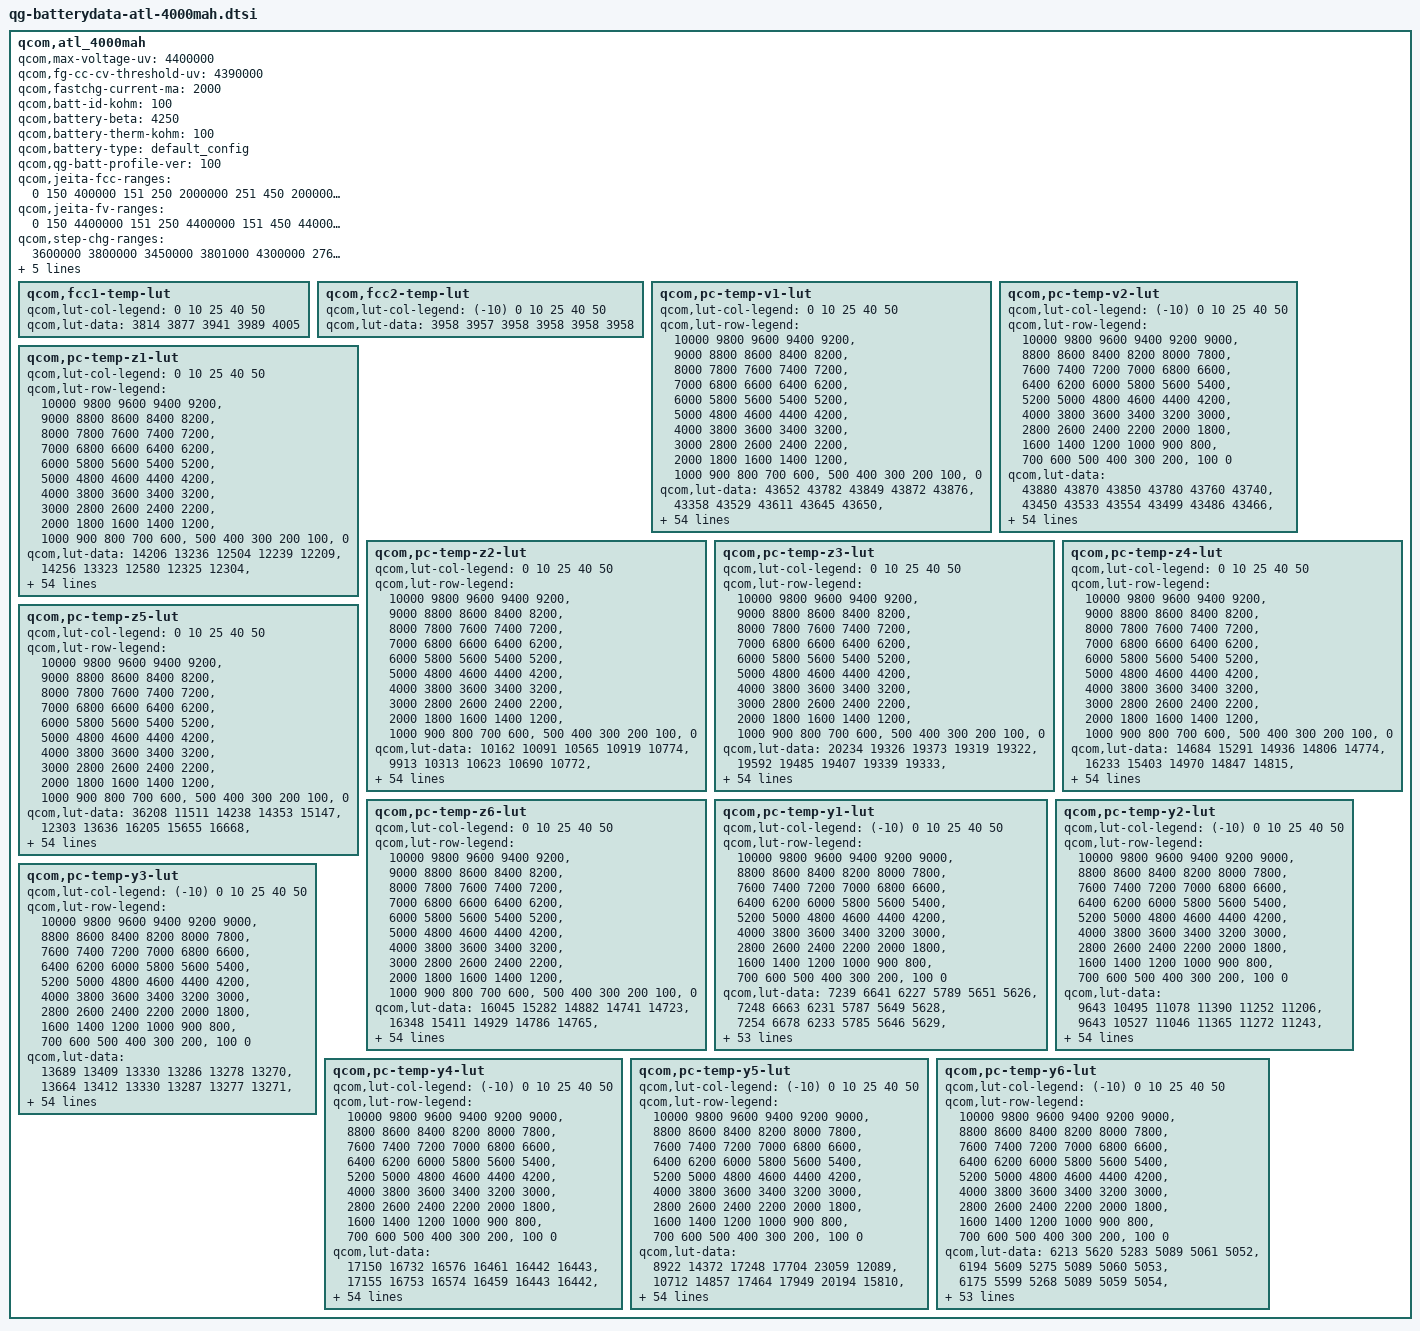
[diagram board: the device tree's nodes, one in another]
// SPDX-License-Identifier: GPL-2.0
/*
 * Copyright (c) 2018-2019, The Linux Foundation. All rights reserved.
 */

qcom,atl_4000mah {
    /* 4124117_LC_M516_ATL_4000mAH_PMI632_averaged_MasterSlave_Jul25th2019 */
	qcom,max-voltage-uv = <4400000>;
	qcom,fg-cc-cv-threshold-uv = <4390000>;
	qcom,fastchg-current-ma = <2000>;
	qcom,batt-id-kohm = <100>;
    	qcom,battery-beta = <4250>;
	qcom,battery-therm-kohm = <100>;
	qcom,battery-type = "default_config";
	qcom,qg-batt-profile-ver = <100>;

	qcom,jeita-fcc-ranges = <0   150   400000
                                151  250  2000000
                                251  450  2000000
                                451  600  2000000>;
        qcom,jeita-fv-ranges = <0    150   4400000
                                151  250  4400000
                                151  450  4400000
                                451  600  4100000>;
	qcom,step-chg-ranges = <3600000  3800000  3450000
				3801000  4300000  2760000
				4301000  4350000  2070000>;

	/* COOL = 15 DegC, WARM = 45 DegC */
	qcom,jeita-soft-thresholds = <0x4621 0x20B8>;
	/* COLD = 0 DegC, HOT = 52 DegC */
	qcom,jeita-hard-thresholds = <0x58CD 0x1A75>;

	qcom,jeita-soft-hys-thresholds = <0x44C4 0x21B5>;
	qcom,jeita-soft-fcc-ua = <500000 2000000>;
	qcom,jeita-soft-fv-uv = <4400000 4100000>;

	qcom,fcc1-temp-lut {
		qcom,lut-col-legend = <0 10 25 40 50>;
		qcom,lut-data = <3814 3877 3941 3989 4005>;
	};

	qcom,fcc2-temp-lut {
		qcom,lut-col-legend = <(-10) 0 10 25 40 50>;
		qcom,lut-data = <3958 3957 3958 3958 3958 3958>;
	};

	qcom,pc-temp-v1-lut {
		qcom,lut-col-legend = <0 10 25 40 50>;
		qcom,lut-row-legend = <10000 9800 9600 9400 9200>,
			<9000 8800 8600 8400 8200>,
			<8000 7800 7600 7400 7200>,
			<7000 6800 6600 6400 6200>,
			<6000 5800 5600 5400 5200>,
			<5000 4800 4600 4400 4200>,
			<4000 3800 3600 3400 3200>,
			<3000 2800 2600 2400 2200>,
			<2000 1800 1600 1400 1200>,
			<1000 900 800 700 600>,
			<500 400 300 200 100>,
			<0>;
		qcom,lut-data = <43652 43782 43849 43872 43876>,
			<43358 43529 43611 43645 43650>,
			<43078 43260 43365 43407 43414>,
			<42809 42984 43105 43154 43168>,
			<42552 42718 42837 42886 42909>,
			<42305 42462 42577 42623 42650>,
			<42066 42214 42322 42371 42398>,
			<41833 41975 42074 42125 42149>,
			<41610 41744 41831 41882 41905>,
			<41399 41520 41595 41645 41666>,
			<41195 41307 41366 41410 41431>,
			<40971 41095 41149 41176 41197>,
			<40710 40865 40929 40947 40967>,
			<40447 40617 40691 40725 40745>,
			<40208 40379 40446 40509 40529>,
			<39980 40153 40229 40302 40322>,
			<39787 39941 40044 40106 40124>,
			<39639 39763 39869 39916 39932>,
			<39511 39616 39698 39734 39744>,
			<39375 39472 39532 39560 39562>,
			<39232 39316 39335 39365 39367>,
			<39091 39153 39064 39105 39127>,
			<38956 38971 38806 38845 38882>,
			<38825 38742 38641 38680 38708>,
			<38705 38532 38513 38562 38580>,
			<38594 38398 38406 38455 38464>,
			<38494 38295 38314 38347 38351>,
			<38404 38222 38236 38249 38247>,
			<38321 38173 38166 38164 38157>,
			<38252 38135 38103 38088 38077>,
			<38198 38100 38051 38026 38010>,
			<38152 38069 38006 37976 37953>,
			<38118 38043 37970 37932 37904>,
			<38094 38023 37943 37895 37861>,
			<38073 38005 37923 37864 37826>,
			<38049 37983 37901 37832 37788>,
			<38027 37959 37876 37801 37748>,
			<37996 37926 37844 37766 37705>,
			<37948 37876 37795 37714 37647>,
			<37877 37801 37717 37637 37571>,
			<37777 37705 37618 37542 37478>,
			<37610 37577 37500 37438 37374>,
			<37320 37358 37315 37284 37223>,
			<36757 36837 36855 36932 36917>,
			<36237 36314 36327 36446 36464>,
			<35877 35901 35900 35984 36001>,
			<35747 35753 35751 35819 35838>,
			<35632 35620 35626 35683 35695>,
			<35508 35509 35502 35555 35566>,
			<35345 35372 35339 35400 35396>,
			<34997 35066 34966 35036 35006>,
			<34446 34538 34428 34509 34484>,
			<33778 33910 33757 33861 33832>,
			<32892 33082 32875 33021 32992>,
			<31612 31893 31570 31811 31771>,
			<30000 30000 30000 30000 30000>;
	};

	qcom,pc-temp-v2-lut {
		qcom,lut-col-legend = <(-10) 0 10 25 40 50>;
		qcom,lut-row-legend = <10000 9800 9600 9400 9200 9000>,
			<8800 8600 8400 8200 8000 7800>,
			<7600 7400 7200 7000 6800 6600>,
			<6400 6200 6000 5800 5600 5400>,
			<5200 5000 4800 4600 4400 4200>,
			<4000 3800 3600 3400 3200 3000>,
			<2800 2600 2400 2200 2000 1800>,
			<1600 1400 1200 1000 900 800>,
			<700 600 500 400 300 200>,
			<100 0>;
		qcom,lut-data = <43880 43870 43850 43780 43760 43740>,
			<43450 43533 43554 43499 43486 43466>,
			<43068 43216 43266 43222 43215 43197>,
			<42744 42917 42984 42948 42945 42929>,
			<42467 42637 42707 42675 42676 42665>,
			<42213 42370 42439 42410 42413 42406>,
			<41968 42114 42183 42153 42161 42153>,
			<41735 41867 41936 41905 41916 41905>,
			<41504 41621 41694 41659 41674 41663>,
			<41275 41371 41455 41417 41434 41426>,
			<41047 41141 41226 41183 41199 41194>,
			<40826 40953 41020 40967 40969 40964>,
			<40603 40779 40822 40757 40744 40738>,
			<40337 40552 40590 40529 40524 40519>,
			<39990 40222 40298 40265 40306 40305>,
			<39662 39901 40020 40023 40098 40099>,
			<39432 39671 39814 39848 39907 39906>,
			<39244 39474 39637 39701 39726 39723>,
			<39059 39278 39441 39525 39538 39533>,
			<38871 39076 39217 39302 39342 39341>,
			<38693 38885 38997 39071 39139 39142>,
			<38531 38711 38804 38854 38917 38921>,
			<38382 38549 38629 38645 38685 38689>,
			<38259 38400 38475 38476 38502 38505>,
			<38163 38252 38341 38344 38364 38366>,
			<38077 38129 38222 38230 38247 38249>,
			<37984 38047 38114 38129 38142 38143>,
			<37889 37985 38016 38037 38050 38049>,
			<37795 37934 37943 37959 37969 37965>,
			<37703 37889 37888 37886 37897 37889>,
			<37609 37852 37846 37828 37836 37824>,
			<37504 37824 37816 37790 37787 37773>,
			<37388 37803 37793 37762 37748 37732>,
			<37260 37779 37769 37737 37707 37686>,
			<37114 37757 37743 37716 37665 37632>,
			<36955 37729 37714 37692 37620 37572>,
			<36789 37682 37679 37652 37563 37501>,
			<36615 37603 37637 37590 37493 37420>,
			<36429 37490 37581 37518 37420 37341>,
			<36199 37286 37507 37447 37356 37278>,
			<35969 36996 37395 37353 37280 37208>,
			<35822 36641 37185 37187 37156 37096>,
			<35725 36188 36778 36874 36947 36908>,
			<35625 35805 36289 36412 36566 36558>,
			<35517 35496 35771 35851 36011 36032>,
			<35380 35286 35451 35531 35649 35666>,
			<35277 35191 35316 35410 35514 35525>,
			<35156 35090 35213 35300 35391 35396>,
			<34992 34978 35077 35178 35263 35269>,
			<34754 34813 34943 35009 35092 35076>,
			<34417 34497 34627 34636 34736 34677>,
			<33949 33992 34106 34077 34189 34131>,
			<33306 33305 33444 33375 33520 33444>,
			<32426 32375 32573 32453 32659 32555>,
			<31107 30949 31315 31083 31426 31328>,
			<26640 26496 29274 26924 29401 29238>;
	};

	qcom,pc-temp-z1-lut {
		qcom,lut-col-legend = <0 10 25 40 50>;
		qcom,lut-row-legend = <10000 9800 9600 9400 9200>,
			<9000 8800 8600 8400 8200>,
			<8000 7800 7600 7400 7200>,
			<7000 6800 6600 6400 6200>,
			<6000 5800 5600 5400 5200>,
			<5000 4800 4600 4400 4200>,
			<4000 3800 3600 3400 3200>,
			<3000 2800 2600 2400 2200>,
			<2000 1800 1600 1400 1200>,
			<1000 900 800 700 600>,
			<500 400 300 200 100>,
			<0>;
		qcom,lut-data = <14206 13236 12504 12239 12209>,
			<14256 13323 12580 12325 12304>,
			<14257 13357 12622 12382 12370>,
			<14259 13378 12630 12400 12393>,
			<14294 13383 12634 12408 12403>,
			<14337 13382 12634 12414 12411>,
			<14344 13381 12627 12418 12419>,
			<14340 13371 12621 12422 12428>,
			<14336 13346 12622 12430 12438>,
			<14340 13335 12625 12442 12450>,
			<14348 13349 12628 12451 12459>,
			<14346 13367 12636 12454 12463>,
			<14274 13362 12641 12457 12466>,
			<14197 13333 12638 12460 12469>,
			<14195 13314 12630 12463 12473>,
			<14215 13323 12628 12466 12477>,
			<14227 13339 12637 12469 12481>,
			<14223 13352 12648 12473 12485>,
			<14213 13363 12655 12477 12490>,
			<14200 13374 12660 12482 12494>,
			<14175 13383 12666 12487 12498>,
			<14156 13392 12670 12492 12502>,
			<14166 13394 12675 12497 12505>,
			<14197 13387 12681 12501 12510>,
			<14225 13381 12687 12505 12514>,
			<14250 13385 12693 12509 12519>,
			<14269 13399 12700 12513 12523>,
			<14271 13412 12707 12518 12527>,
			<14268 13420 12712 12523 12531>,
			<14262 13427 12717 12527 12535>,
			<14248 13435 12721 12531 12539>,
			<14227 13441 12726 12534 12541>,
			<14223 13450 12731 12537 12544>,
			<14242 13462 12735 12541 12546>,
			<14269 13476 12740 12543 12548>,
			<14294 13483 12743 12546 12551>,
			<14321 13486 12746 12548 12552>,
			<14333 13490 12749 12549 12554>,
			<14323 13498 12754 12550 12556>,
			<14309 13511 12762 12551 12558>,
			<14311 13524 12767 12553 12559>,
			<14339 13536 12769 12555 12560>,
			<14378 13549 12772 12559 12562>,
			<14432 13563 12796 12570 12573>,
			<14473 13604 12860 12608 12602>,
			<14425 13648 12909 12666 12648>,
			<14418 13630 12941 12686 12666>,
			<14449 13669 12948 12701 12678>,
			<14419 13680 12955 12710 12693>,
			<14479 13713 12987 12731 12708>,
			<14481 13734 13002 12746 12720>,
			<14506 13741 13029 12770 12741>,
			<14500 13773 13049 12797 12762>,
			<14568 13812 13083 12830 12789>,
			<14568 13812 13083 12830 12789>,
			<14568 13812 13083 12830 12789>;
	};

	qcom,pc-temp-z2-lut {
		qcom,lut-col-legend = <0 10 25 40 50>;
		qcom,lut-row-legend = <10000 9800 9600 9400 9200>,
			<9000 8800 8600 8400 8200>,
			<8000 7800 7600 7400 7200>,
			<7000 6800 6600 6400 6200>,
			<6000 5800 5600 5400 5200>,
			<5000 4800 4600 4400 4200>,
			<4000 3800 3600 3400 3200>,
			<3000 2800 2600 2400 2200>,
			<2000 1800 1600 1400 1200>,
			<1000 900 800 700 600>,
			<500 400 300 200 100>,
			<0>;
		qcom,lut-data = <10162 10091 10565 10919 10774>,
			<9913 10313 10623 10690 10772>,
			<9999 10313 10644 10564 10767>,
			<10074 10302 10606 10583 10758>,
			<10134 10287 10535 10670 10735>,
			<10178 10263 10510 10710 10702>,
			<10182 10238 10505 10700 10641>,
			<10164 10218 10500 10681 10573>,
			<10145 10201 10488 10647 10556>,
			<10135 10195 10473 10588 10552>,
			<10127 10195 10469 10563 10547>,
			<10117 10196 10478 10580 10515>,
			<10097 10203 10492 10602 10474>,
			<10078 10230 10510 10589 10474>,
			<10069 10257 10532 10537 10509>,
			<10065 10272 10550 10511 10537>,
			<10061 10286 10563 10524 10546>,
			<10056 10305 10573 10541 10554>,
			<10052 10333 10579 10549 10571>,
			<10052 10359 10583 10552 10604>,
			<10058 10374 10584 10558 10623>,
			<10067 10387 10583 10590 10613>,
			<10082 10406 10581 10626 10598>,
			<10104 10445 10569 10616 10599>,
			<10127 10476 10541 10559 10624>,
			<10149 10477 10530 10528 10657>,
			<10170 10474 10546 10618 10712>,
			<10190 10471 10570 10736 10765>,
			<10207 10467 10587 10740 10757>,
			<10224 10464 10604 10679 10670>,
			<10246 10464 10609 10621 10574>,
			<10268 10465 10597 10577 10479>,
			<10280 10468 10582 10545 10398>,
			<10285 10472 10583 10543 10397>,
			<10290 10479 10595 10554 10466>,
			<10295 10487 10606 10571 10532>,
			<10300 10496 10614 10598 10569>,
			<10307 10506 10622 10628 10597>,
			<10325 10519 10635 10638 10610>,
			<10346 10534 10654 10643 10615>,
			<10353 10538 10663 10647 10623>,
			<10356 10534 10652 10656 10646>,
			<10356 10525 10627 10666 10664>,
			<10349 10463 10540 10673 10592>,
			<10319 10326 10525 10585 10453>,
			<10063 10348 10559 10569 10361>,
			<9833 10365 10600 10570 10422>,
			<9504 10405 10584 10552 10476>,
			<9440 10383 10589 10590 10573>,
			<9421 10034 10644 10664 10707>,
			<9425 10048 10634 10639 10482>,
			<9374 10224 10465 10495 10423>,
			<9341 9791 10287 10417 10357>,
			<9320 9719 10033 10250 10286>,
			<9320 9719 10033 10250 10286>,
			<9320 9719 10033 10250 10286>;
	};

	qcom,pc-temp-z3-lut {
		qcom,lut-col-legend = <0 10 25 40 50>;
		qcom,lut-row-legend = <10000 9800 9600 9400 9200>,
			<9000 8800 8600 8400 8200>,
			<8000 7800 7600 7400 7200>,
			<7000 6800 6600 6400 6200>,
			<6000 5800 5600 5400 5200>,
			<5000 4800 4600 4400 4200>,
			<4000 3800 3600 3400 3200>,
			<3000 2800 2600 2400 2200>,
			<2000 1800 1600 1400 1200>,
			<1000 900 800 700 600>,
			<500 400 300 200 100>,
			<0>;
		qcom,lut-data = <20234 19326 19373 19319 19322>,
			<19592 19485 19407 19339 19333>,
			<19719 19546 19429 19356 19343>,
			<19781 19583 19438 19373 19351>,
			<19757 19593 19443 19389 19359>,
			<19718 19595 19445 19394 19365>,
			<19692 19596 19447 19394 19368>,
			<19669 19592 19447 19392 19371>,
			<19657 19579 19444 19388 19371>,
			<19663 19570 19436 19378 19367>,
			<19678 19565 19428 19372 19363>,
			<19686 19561 19419 19371 19360>,
			<19688 19555 19412 19370 19357>,
			<19689 19545 19410 19366 19353>,
			<19688 19533 19408 19358 19348>,
			<19683 19519 19405 19354 19344>,
			<19675 19505 19395 19353 19340>,
			<19664 19499 19387 19352 19337>,
			<19652 19495 19387 19350 19336>,
			<19648 19494 19387 19348 19337>,
			<19647 19495 19390 19346 19338>,
			<19647 19500 19403 19351 19338>,
			<19652 19507 19416 19356 19337>,
			<19666 19525 19415 19354 19334>,
			<19674 19539 19409 19342 19329>,
			<19676 19540 19406 19336 19326>,
			<19677 19539 19404 19347 19346>,
			<19677 19538 19404 19364 19375>,
			<19677 19533 19404 19372 19379>,
			<19675 19527 19408 19378 19375>,
			<19672 19524 19412 19380 19370>,
			<19667 19522 19416 19379 19365>,
			<19661 19520 19418 19376 19360>,
			<19654 19516 19417 19372 19353>,
			<19646 19511 19412 19368 19345>,
			<19638 19508 19407 19363 19338>,
			<19628 19507 19403 19357 19335>,
			<19619 19505 19399 19351 19332>,
			<19611 19501 19395 19348 19328>,
			<19602 19497 19392 19345 19324>,
			<19589 19491 19391 19344 19321>,
			<19570 19481 19391 19344 19321>,
			<19569 19479 19393 19344 19322>,
			<19600 19509 19413 19365 19346>,
			<19580 19494 19411 19369 19357>,
			<19579 19479 19400 19365 19357>,
			<19529 19467 19393 19361 19347>,
			<19452 19465 19383 19350 19341>,
			<19436 19439 19378 19346 19332>,
			<19429 19391 19373 19335 19326>,
			<19475 19404 19367 19349 19349>,
			<19506 19464 19378 19361 19349>,
			<19530 19434 19383 19367 19356>,
			<19566 19452 19383 19368 19352>,
			<19566 19452 19383 19368 19352>,
			<19566 19452 19383 19368 19352>;
	};

	qcom,pc-temp-z4-lut {
		qcom,lut-col-legend = <0 10 25 40 50>;
		qcom,lut-row-legend = <10000 9800 9600 9400 9200>,
			<9000 8800 8600 8400 8200>,
			<8000 7800 7600 7400 7200>,
			<7000 6800 6600 6400 6200>,
			<6000 5800 5600 5400 5200>,
			<5000 4800 4600 4400 4200>,
			<4000 3800 3600 3400 3200>,
			<3000 2800 2600 2400 2200>,
			<2000 1800 1600 1400 1200>,
			<1000 900 800 700 600>,
			<500 400 300 200 100>,
			<0>;
		qcom,lut-data = <14684 15291 14936 14806 14774>,
			<16233 15403 14970 14847 14815>,
			<16176 15354 14979 14866 14837>,
			<16098 15229 14950 14858 14836>,
			<15967 15125 14888 14825 14812>,
			<15806 15041 14840 14793 14786>,
			<15679 14970 14803 14769 14765>,
			<15572 14920 14772 14749 14746>,
			<15474 14881 14748 14732 14728>,
			<15383 14849 14729 14719 14712>,
			<15298 14823 14719 14707 14700>,
			<15220 14801 14713 14698 14693>,
			<15144 14778 14709 14690 14687>,
			<15078 14754 14705 14685 14681>,
			<15030 14743 14702 14681 14674>,
			<14992 14744 14697 14677 14668>,
			<14960 14747 14687 14667 14660>,
			<14931 14745 14678 14658 14654>,
			<14906 14732 14673 14657 14653>,
			<14885 14721 14670 14658 14655>,
			<14866 14721 14673 14661 14658>,
			<14851 14721 14734 14721 14706>,
			<14838 14725 14796 14796 14776>,
			<14826 14775 14805 14805 14789>,
			<14822 14831 14808 14803 14786>,
			<14825 14848 14808 14799 14780>,
			<14832 14858 14797 14777 14749>,
			<14839 14861 14779 14746 14705>,
			<14850 14852 14764 14724 14689>,
			<14858 14837 14748 14706 14682>,
			<14859 14824 14733 14693 14677>,
			<14860 14813 14720 14684 14672>,
			<14860 14802 14708 14676 14668>,
			<14855 14790 14701 14672 14667>,
			<14848 14779 14695 14669 14667>,
			<14841 14771 14692 14668 14667>,
			<14832 14766 14692 14668 14667>,
			<14822 14762 14692 14668 14666>,
			<14809 14760 14694 14670 14667>,
			<14793 14759 14701 14677 14673>,
			<14776 14755 14705 14681 14676>,
			<14757 14728 14693 14676 14671>,
			<14762 14717 14683 14671 14666>,
			<14817 14765 14731 14706 14690>,
			<14773 14743 14724 14713 14699>,
			<14769 14713 14689 14693 14691>,
			<14808 14702 14675 14679 14679>,
			<14884 14689 14663 14664 14661>,
			<14898 14696 14656 14653 14652>,
			<14905 14751 14661 14657 14652>,
			<14883 14752 14688 14662 14652>,
			<14910 14718 14686 14657 14654>,
			<14940 14788 14695 14655 14653>,
			<14975 14814 14718 14665 14659>,
			<14975 14814 14718 14665 14659>,
			<14975 14814 14718 14665 14659>;
	};

	qcom,pc-temp-z5-lut {
		qcom,lut-col-legend = <0 10 25 40 50>;
		qcom,lut-row-legend = <10000 9800 9600 9400 9200>,
			<9000 8800 8600 8400 8200>,
			<8000 7800 7600 7400 7200>,
			<7000 6800 6600 6400 6200>,
			<6000 5800 5600 5400 5200>,
			<5000 4800 4600 4400 4200>,
			<4000 3800 3600 3400 3200>,
			<3000 2800 2600 2400 2200>,
			<2000 1800 1600 1400 1200>,
			<1000 900 800 700 600>,
			<500 400 300 200 100>,
			<0>;
		qcom,lut-data = <36208 11511 14238 14353 15147>,
			<12303 13636 16205 15655 16668>,
			<13150 14889 17545 17014 17916>,
			<13653 15814 18150 18544 18798>,
			<13745 16560 18566 20221 19410>,
			<13809 17208 19246 21292 20089>,
			<13920 17710 20442 21921 21153>,
			<14083 18011 21381 22289 22301>,
			<14310 18211 21716 22216 23035>,
			<14695 18524 21929 21875 23515>,
			<15264 19232 21971 21745 24015>,
			<15850 20198 21952 22939 24756>,
			<16469 21296 21936 24360 25477>,
			<17096 22691 22560 24315 25784>,
			<17703 23390 23932 23609 25911>,
			<18317 22546 24290 23287 26116>,
			<18732 21213 23218 24840 26916>,
			<18901 21017 22222 26982 28367>,
			<19029 21926 22635 27760 30654>,
			<19302 23322 24303 28125 34724>,
			<19952 25047 27339 28511 36977>,
			<20962 27623 38097 29145 33394>,
			<22899 31787 47713 29675 26770>,
			<26152 42255 44540 27972 22121>,
			<29085 51109 33784 21115 18139>,
			<31508 49989 27072 17392 16396>,
			<33647 44316 24046 18061 19085>,
			<35418 39326 22362 19401 23557>,
			<37091 35566 22345 21034 25962>,
			<37917 32664 22753 23368 27431>,
			<37891 31532 23421 25594 28678>,
			<37795 30965 25689 27542 30090>,
			<37541 30515 27959 29224 31213>,
			<36130 29982 28107 30350 31117>,
			<34300 29548 27745 31256 29469>,
			<32870 29535 27271 31611 27631>,
			<31501 30049 26598 29708 26341>,
			<30796 30462 25752 26403 25052>,
			<30657 30254 24782 24051 23197>,
			<30558 29646 23595 21965 20361>,
			<29847 28922 23087 21036 18825>,
			<27146 27812 25008 21131 18834>,
			<26948 27629 26572 21387 18875>,
			<31101 31528 25961 23120 21635>,
			<32247 30179 26814 22948 22199>,
			<25114 30308 30551 24233 23019>,
			<18965 28507 30785 26671 22868>,
			<13581 31729 28956 26995 26720>,
			<12994 23969 29476 29698 27781>,
			<12729 15954 27077 23038 22799>,
			<13761 17056 20163 21422 25398>,
			<13893 22913 20761 25590 24370>,
			<13588 15616 19270 26654 26998>,
			<13603 14825 16731 23156 22137>,
			<13603 14825 16731 23156 22137>,
			<13603 14825 16731 23156 22137>;
	};

	qcom,pc-temp-z6-lut {
		qcom,lut-col-legend = <0 10 25 40 50>;
		qcom,lut-row-legend = <10000 9800 9600 9400 9200>,
			<9000 8800 8600 8400 8200>,
			<8000 7800 7600 7400 7200>,
			<7000 6800 6600 6400 6200>,
			<6000 5800 5600 5400 5200>,
			<5000 4800 4600 4400 4200>,
			<4000 3800 3600 3400 3200>,
			<3000 2800 2600 2400 2200>,
			<2000 1800 1600 1400 1200>,
			<1000 900 800 700 600>,
			<500 400 300 200 100>,
			<0>;
		qcom,lut-data = <16045 15282 14882 14741 14723>,
			<16348 15411 14929 14786 14765>,
			<16339 15398 14949 14813 14791>,
			<16323 15357 14938 14814 14795>,
			<16238 15316 14915 14811 14791>,
			<16110 15273 14896 14805 14786>,
			<16018 15231 14880 14797 14781>,
			<15943 15199 14865 14788 14776>,
			<15881 15170 14852 14779 14770>,
			<15835 15148 14841 14770 14763>,
			<15798 15132 14832 14763 14757>,
			<15755 15118 14826 14759 14753>,
			<15703 15099 14821 14755 14749>,
			<15653 15076 14817 14751 14745>,
			<15616 15061 14813 14746 14740>,
			<15586 15054 14808 14742 14736>,
			<15562 15049 14800 14737 14731>,
			<15542 15045 14794 14733 14727>,
			<15526 15040 14793 14733 14726>,
			<15513 15038 14794 14733 14728>,
			<15502 15039 14796 14734 14730>,
			<15495 15043 14831 14763 14752>,
			<15496 15051 14866 14799 14782>,
			<15501 15084 14868 14803 14788>,
			<15506 15116 14869 14797 14785>,
			<15512 15125 14869 14792 14782>,
			<15518 15130 14864 14789 14780>,
			<15523 15132 14858 14787 14777>,
			<15529 15127 14853 14783 14773>,
			<15532 15119 14849 14779 14769>,
			<15532 15113 14846 14775 14765>,
			<15531 15109 14843 14771 14760>,
			<15530 15104 14840 14766 14756>,
			<15526 15097 14836 14762 14751>,
			<15521 15091 14831 14759 14748>,
			<15516 15089 14827 14756 14744>,
			<15510 15088 14825 14752 14742>,
			<15504 15087 14824 14750 14739>,
			<15498 15086 14824 14750 14739>,
			<15491 15086 14827 14751 14739>,
			<15482 15083 14828 14752 14740>,
			<15471 15070 14824 14750 14738>,
			<15477 15067 14821 14749 14736>,
			<15537 15117 14862 14778 14759>,
			<15559 15134 14873 14793 14780>,
			<15571 15142 14872 14793 14784>,
			<15572 15142 14867 14788 14776>,
			<15572 15144 14862 14778 14767>,
			<15582 15146 14861 14773 14759>,
			<15601 15155 14868 14772 14758>,
			<15632 15179 14885 14786 14773>,
			<15674 15213 14901 14795 14778>,
			<15722 15243 14920 14805 14787>,
			<15783 15286 14947 14818 14794>,
			<15783 15286 14947 14818 14794>,
			<15783 15286 14947 14818 14794>;
	};

	qcom,pc-temp-y1-lut {
		qcom,lut-col-legend = <(-10) 0 10 25 40 50>;
		qcom,lut-row-legend = <10000 9800 9600 9400 9200 9000>,
			<8800 8600 8400 8200 8000 7800>,
			<7600 7400 7200 7000 6800 6600>,
			<6400 6200 6000 5800 5600 5400>,
			<5200 5000 4800 4600 4400 4200>,
			<4000 3800 3600 3400 3200 3000>,
			<2800 2600 2400 2200 2000 1800>,
			<1600 1400 1200 1000 900 800>,
			<700 600 500 400 300 200>,
			<100 0>;
		qcom,lut-data = <7239 6641 6227 5789 5651 5626>,
			<7248 6663 6231 5787 5649 5628>,
			<7254 6678 6233 5785 5646 5629>,
			<7257 6688 6231 5783 5643 5630>,
			<7258 6693 6229 5780 5640 5631>,
			<7258 6695 6225 5777 5639 5631>,
			<7250 6690 6218 5775 5638 5631>,
			<7235 6681 6210 5772 5638 5630>,
			<7234 6681 6206 5769 5638 5630>,
			<7253 6693 6203 5767 5638 5630>,
			<7268 6703 6202 5766 5639 5631>,
			<7265 6688 6202 5764 5641 5632>,
			<7257 6660 6203 5763 5643 5635>,
			<7255 6656 6203 5763 5645 5638>,
			<7262 6689 6202 5767 5647 5640>,
			<7271 6717 6202 5772 5649 5643>,
			<7278 6717 6208 5775 5650 5645>,
			<7285 6714 6220 5777 5652 5647>,
			<7285 6714 6223 5780 5654 5649>,
			<7263 6720 6220 5784 5657 5652>,
			<7240 6726 6215 5788 5660 5654>,
			<7263 6722 6211 5791 5662 5657>,
			<7328 6713 6207 5793 5663 5659>,
			<7354 6710 6206 5795 5664 5661>,
			<7344 6725 6215 5798 5668 5663>,
			<7333 6742 6226 5801 5671 5665>,
			<7333 6749 6231 5805 5674 5667>,
			<7336 6754 6234 5809 5676 5670>,
			<7341 6759 6238 5812 5679 5673>,
			<7346 6764 6241 5816 5683 5675>,
			<7352 6768 6245 5819 5687 5677>,
			<7360 6765 6248 5821 5688 5680>,
			<7371 6752 6252 5822 5690 5683>,
			<7376 6747 6256 5824 5691 5685>,
			<7356 6773 6265 5827 5692 5687>,
			<7329 6802 6275 5830 5694 5688>,
			<7334 6804 6282 5833 5696 5691>,
			<7375 6798 6287 5838 5698 5693>,
			<7401 6792 6292 5843 5700 5695>,
			<7402 6788 6297 5850 5702 5696>,
			<7402 6784 6303 5859 5705 5696>,
			<7407 6797 6312 5873 5711 5699>,
			<7428 6838 6326 5895 5724 5710>,
			<7457 6842 6344 5916 5744 5726>,
			<7492 6837 6358 5936 5770 5747>,
			<7507 6887 6345 5953 5783 5759>,
			<7514 6900 6387 5953 5792 5765>,
			<7549 6890 6382 5962 5802 5773>,
			<7649 6937 6402 5982 5804 5778>,
			<7804 6949 6398 5989 5812 5783>,
			<7967 7126 6434 6007 5825 5794>,
			<8015 7254 6425 6014 5841 5807>,
			<8166 7286 6506 6058 5862 5822>,
			<8327 7418 6668 6092 5886 5845>,
			<8327 7418 6668 6092 5886 5845>,
			<8327 7418 6668 6092 5886 5845>;
	};

	qcom,pc-temp-y2-lut {
		qcom,lut-col-legend = <(-10) 0 10 25 40 50>;
		qcom,lut-row-legend = <10000 9800 9600 9400 9200 9000>,
			<8800 8600 8400 8200 8000 7800>,
			<7600 7400 7200 7000 6800 6600>,
			<6400 6200 6000 5800 5600 5400>,
			<5200 5000 4800 4600 4400 4200>,
			<4000 3800 3600 3400 3200 3000>,
			<2800 2600 2400 2200 2000 1800>,
			<1600 1400 1200 1000 900 800>,
			<700 600 500 400 300 200>,
			<100 0>;
		qcom,lut-data = <9643 10495 11078 11390 11252 11206>,
			<9643 10527 11046 11365 11272 11243>,
			<9643 10558 11014 11340 11281 11259>,
			<9881 10586 10985 11315 11281 11258>,
			<10204 10612 10960 11291 11276 11246>,
			<10405 10634 10940 11267 11267 11228>,
			<10495 10653 10924 11245 11252 11191>,
			<10554 10669 10911 11223 11230 11145>,
			<10602 10687 10903 11190 11210 11136>,
			<10642 10704 10897 11136 11192 11148>,
			<10678 10727 10894 11102 11173 11158>,
			<10722 10792 10900 11102 11146 11139>,
			<10765 10883 10918 11103 11117 11102>,
			<10773 10913 10941 11108 11117 11093>,
			<10744 10917 10984 11142 11177 11109>,
			<10718 10922 11030 11186 11232 11136>,
			<10723 10932 11071 11225 11242 11174>,
			<10735 10946 11110 11264 11247 11233>,
			<10740 10958 11123 11283 11271 11317>,
			<10738 10968 11125 11292 11427 11480>,
			<10734 10975 11127 11297 11565 11603>,
			<10726 10979 11130 11296 11503 11529>,
			<10706 10982 11135 11295 11342 11339>,
			<10686 10983 11142 11297 11288 11273>,
			<10666 10980 11160 11341 11343 11324>,
			<10642 10977 11176 11388 11402 11376>,
			<10604 10980 11181 11395 11415 11382>,
			<10548 10991 11184 11398 11421 11383>,
			<10502 11002 11187 11399 11426 11388>,
			<10479 11014 11189 11397 11431 11435>,
			<10453 11028 11193 11395 11436 11483>,
			<10314 11042 11198 11394 11446 11471>,
			<9929 11057 11206 11393 11459 11417>,
			<9719 11062 11216 11392 11464 11371>,
			<9709 11058 11232 11392 11448 11341>,
			<9703 11050 11252 11392 11422 11317>,
			<9696 11023 11269 11390 11399 11298>,
			<9690 10951 11284 11382 11375 11281>,
			<9684 10876 11308 11374 11356 11275>,
			<9678 10816 11385 11364 11342 11284>,
			<9672 10752 11466 11354 11332 11303>,
			<9669 10674 11441 11348 11373 11342>,
			<9666 10571 11287 11344 11508 11408>,
			<9664 10247 11130 11318 11446 11395>,
			<9662 9783 10974 11259 11265 11316>,
			<9659 9725 10825 11230 11362 11253>,
			<9659 9701 10331 11245 11319 11122>,
			<9657 9683 10639 11272 11364 11173>,
			<9654 9669 10236 11141 11286 11164>,
			<9651 9660 10436 11016 11305 11208>,
			<9651 9656 9964 10698 11184 11079>,
			<9650 9653 9733 10485 11021 11076>,
			<9649 9651 9666 10310 10997 10938>,
			<9649 9651 9656 10095 10841 10791>,
			<9649 9651 9656 10095 10841 10791>,
			<9649 9651 9656 10095 10841 10791>;
	};

	qcom,pc-temp-y3-lut {
		qcom,lut-col-legend = <(-10) 0 10 25 40 50>;
		qcom,lut-row-legend = <10000 9800 9600 9400 9200 9000>,
			<8800 8600 8400 8200 8000 7800>,
			<7600 7400 7200 7000 6800 6600>,
			<6400 6200 6000 5800 5600 5400>,
			<5200 5000 4800 4600 4400 4200>,
			<4000 3800 3600 3400 3200 3000>,
			<2800 2600 2400 2200 2000 1800>,
			<1600 1400 1200 1000 900 800>,
			<700 600 500 400 300 200>,
			<100 0>;
		qcom,lut-data = <13689 13409 13330 13286 13278 13270>,
			<13664 13412 13330 13287 13277 13271>,
			<13632 13415 13331 13287 13276 13273>,
			<13599 13417 13331 13288 13276 13274>,
			<13571 13419 13332 13289 13277 13276>,
			<13555 13419 13334 13289 13277 13276>,
			<13549 13419 13335 13291 13279 13276>,
			<13546 13418 13337 13292 13282 13277>,
			<13539 13417 13339 13292 13284 13277>,
			<13524 13415 13340 13292 13285 13279>,
			<13513 13414 13342 13292 13285 13281>,
			<13512 13411 13344 13293 13285 13282>,
			<13511 13409 13345 13297 13285 13282>,
			<13508 13406 13345 13298 13285 13282>,
			<13493 13404 13343 13299 13287 13282>,
			<13478 13402 13341 13299 13289 13283>,
			<13472 13399 13341 13300 13289 13283>,
			<13468 13395 13341 13301 13289 13284>,
			<13466 13391 13341 13301 13289 13285>,
			<13464 13387 13337 13300 13288 13286>,
			<13462 13383 13332 13299 13288 13286>,
			<13460 13381 13328 13296 13286 13284>,
			<13456 13380 13324 13290 13282 13278>,
			<13455 13379 13323 13288 13279 13275>,
			<13455 13375 13322 13287 13277 13274>,
			<13455 13373 13321 13287 13276 13274>,
			<13456 13373 13321 13287 13276 13274>,
			<13456 13375 13322 13288 13277 13275>,
			<13457 13376 13322 13289 13278 13275>,
			<13459 13377 13323 13290 13279 13275>,
			<13462 13378 13324 13291 13279 13274>,
			<13474 13379 13327 13292 13280 13274>,
			<13506 13382 13330 13293 13281 13276>,
			<13533 13383 13332 13295 13282 13277>,
			<13544 13385 13333 13297 13282 13278>,
			<13554 13386 13334 13298 13282 13279>,
			<13570 13385 13335 13299 13283 13279>,
			<13594 13383 13336 13299 13283 13277>,
			<13616 13382 13337 13300 13284 13277>,
			<13628 13381 13340 13302 13286 13280>,
			<13641 13380 13342 13305 13289 13285>,
			<13672 13378 13341 13306 13291 13287>,
			<13752 13376 13336 13305 13294 13289>,
			<13843 13378 13328 13301 13291 13287>,
			<13957 13388 13321 13294 13285 13282>,
			<14161 13432 13319 13292 13285 13282>,
			<14176 13453 13306 13293 13286 13282>,
			<14422 13516 13324 13296 13288 13282>,
			<15105 13645 13323 13297 13289 13287>,
			<16565 13920 13349 13297 13291 13287>,
			<19381 14527 13358 13293 13288 13283>,
			<24324 15919 13431 13300 13286 13286>,
			<32719 18347 13735 13313 13292 13288>,
			<46577 22623 14705 13339 13299 13292>,
			<46577 22623 14705 13339 13299 13292>,
			<46577 22623 14705 13339 13299 13292>;
	};

	qcom,pc-temp-y4-lut {
		qcom,lut-col-legend = <(-10) 0 10 25 40 50>;
		qcom,lut-row-legend = <10000 9800 9600 9400 9200 9000>,
			<8800 8600 8400 8200 8000 7800>,
			<7600 7400 7200 7000 6800 6600>,
			<6400 6200 6000 5800 5600 5400>,
			<5200 5000 4800 4600 4400 4200>,
			<4000 3800 3600 3400 3200 3000>,
			<2800 2600 2400 2200 2000 1800>,
			<1600 1400 1200 1000 900 800>,
			<700 600 500 400 300 200>,
			<100 0>;
		qcom,lut-data = <17150 16732 16576 16461 16442 16443>,
			<17155 16753 16574 16459 16443 16442>,
			<17164 16774 16572 16458 16445 16442>,
			<17175 16794 16571 16458 16446 16442>,
			<17188 16811 16570 16459 16447 16442>,
			<17204 16825 16570 16460 16448 16443>,
			<17221 16837 16570 16462 16448 16444>,
			<17241 16846 16571 16465 16449 16447>,
			<17264 16857 16573 16469 16449 16449>,
			<17296 16866 16582 16477 16453 16450>,
			<17315 16880 16597 16486 16457 16452>,
			<17311 16932 16624 16495 16464 16456>,
			<17296 17007 16659 16506 16472 16461>,
			<17268 17016 16667 16515 16478 16466>,
			<17173 16917 16662 16521 16482 16472>,
			<17095 16834 16657 16529 16487 16478>,
			<17106 16844 16667 16550 16500 16487>,
			<17138 16871 16686 16579 16521 16498>,
			<17150 16878 16689 16587 16533 16508>,
			<17150 16864 16647 16568 16540 16518>,
			<17150 16847 16601 16540 16544 16525>,
			<17152 16839 16584 16510 16522 16507>,
			<17158 16833 16573 16476 16469 16464>,
			<17167 16832 16570 16466 16450 16447>,
			<17192 16836 16573 16466 16449 16445>,
			<17217 16844 16578 16467 16449 16444>,
			<17224 16866 16583 16470 16451 16446>,
			<17227 16912 16590 16474 16456 16451>,
			<17228 16957 16600 16479 16462 16457>,
			<17224 16995 16622 16483 16469 16465>,
			<17216 17034 16651 16489 16476 16473>,
			<17204 17079 16680 16498 16483 16480>,
			<17181 17130 16712 16510 16490 16486>,
			<17151 17180 16746 16524 16492 16488>,
			<17107 17234 16784 16538 16492 16483>,
			<17052 17281 16825 16550 16491 16477>,
			<16992 17313 16869 16557 16490 16474>,
			<16922 17339 16917 16561 16487 16472>,
			<16864 17348 16966 16568 16486 16471>,
			<16817 17283 17025 16603 16501 16482>,
			<16783 17156 17072 16641 16527 16502>,
			<16782 16982 17043 16646 16550 16521>,
			<16812 16742 16892 16644 16573 16542>,
			<16851 16650 16713 16601 16555 16529>,
			<16891 16622 16554 16503 16498 16489>,
			<16895 16637 16524 16490 16481 16478>,
			<16834 16650 16537 16486 16476 16471>,
			<16840 16685 16527 16496 16478 16476>,
			<16948 16726 16567 16510 16485 16480>,
			<17251 16770 16584 16523 16488 16484>,
			<17912 16792 16607 16498 16473 16468>,
			<19221 17014 16610 16492 16470 16469>,
			<22007 17636 16668 16502 16480 16478>,
			<28865 19440 16845 16534 16510 16503>,
			<28865 19440 16845 16534 16510 16503>,
			<28865 19440 16845 16534 16510 16503>;
	};

	qcom,pc-temp-y5-lut {
		qcom,lut-col-legend = <(-10) 0 10 25 40 50>;
		qcom,lut-row-legend = <10000 9800 9600 9400 9200 9000>,
			<8800 8600 8400 8200 8000 7800>,
			<7600 7400 7200 7000 6800 6600>,
			<6400 6200 6000 5800 5600 5400>,
			<5200 5000 4800 4600 4400 4200>,
			<4000 3800 3600 3400 3200 3000>,
			<2800 2600 2400 2200 2000 1800>,
			<1600 1400 1200 1000 900 800>,
			<700 600 500 400 300 200>,
			<100 0>;
		qcom,lut-data = <8922 14372 17248 17704 23059 12089>,
			<10712 14857 17464 17949 20194 15810>,
			<12468 15466 17596 18030 18446 18192>,
			<14102 16070 17665 17985 17537 19530>,
			<15525 16537 17691 17849 17193 20120>,
			<16647 16736 17695 17658 17139 20255>,
			<17575 16690 17630 17398 18075 19359>,
			<18299 16574 17471 17033 19699 17804>,
			<18514 16421 17276 16521 20021 17565>,
			<18551 16151 16986 15637 19416 18525>,
			<18601 15976 16669 15069 18573 19265>,
			<19755 16249 16320 15085 17441 18787>,
			<21983 16970 15989 15144 16188 17674>,
			<22473 17863 16075 15196 15912 16820>,
			<20643 19338 17571 15234 16231 16100>,
			<19014 20348 19136 15292 16500 15650>,
			<19012 19955 19764 15513 16175 15548>,
			<19204 19027 20193 16057 15460 15492>,
			<19441 18639 20547 17056 15439 15644>,
			<19800 18544 20902 20152 17774 17528>,
			<20167 18500 21111 22701 20258 19672>,
			<20384 18588 20670 21787 21114 20713>,
			<20542 18802 19506 19234 21660 21476>,
			<20799 18835 18807 17959 21659 21582>,
			<21428 18208 18540 17559 19645 20106>,
			<22148 17587 18314 17360 17646 18601>,
			<22589 17604 17994 17494 17546 18438>,
			<22914 17791 17628 17890 17637 18405>,
			<23293 17999 17312 18084 17777 18293>,
			<23871 18211 17003 18124 18124 17367>,
			<24427 18471 16796 18143 18546 16416>,
			<24721 18828 16809 18144 18874 16622>,
			<24921 19310 16896 18142 19174 17627>,
			<25033 19832 16931 18150 19276 18592>,
			<25079 20389 16800 18451 19143 19522>,
			<25115 20989 16647 18803 18912 20205>,
			<25212 21606 16659 18718 18680 19701>,
			<25419 22248 16800 18233 18406 17731>,
			<25527 23000 17037 17774 18131 16745>,
			<21423 24234 17815 17382 17804 17471>,
			<15074 25314 19100 17091 17544 18391>,
			<13399 25371 20773 17228 17522 18323>,
			<13124 24906 22956 18096 17585 17686>,
			<12918 21586 23934 20072 18720 18402>,
			<12777 15041 24267 22380 21021 20153>,
			<13316 14029 20951 20848 21049 19633>,
			<13344 13275 14923 20162 20214 18191>,
			<13520 13248 19252 20378 19903 16920>,
			<12634 13581 15028 18248 18284 19047>,
			<11382 13717 18062 16653 19026 19223>,
			<10318 13052 14122 16128 21100 19134>,
			<9621 11293 13436 17395 18886 23004>,
			<9223 10240 13504 18064 22803 22783>,
			<9010 9476 11946 17483 25801 23944>,
			<9010 9476 11946 17483 25801 23944>,
			<9010 9476 11946 17483 25801 23944>;
	};

	qcom,pc-temp-y6-lut {
		qcom,lut-col-legend = <(-10) 0 10 25 40 50>;
		qcom,lut-row-legend = <10000 9800 9600 9400 9200 9000>,
			<8800 8600 8400 8200 8000 7800>,
			<7600 7400 7200 7000 6800 6600>,
			<6400 6200 6000 5800 5600 5400>,
			<5200 5000 4800 4600 4400 4200>,
			<4000 3800 3600 3400 3200 3000>,
			<2800 2600 2400 2200 2000 1800>,
			<1600 1400 1200 1000 900 800>,
			<700 600 500 400 300 200>,
			<100 0>;
		qcom,lut-data = <6213 5620 5283 5089 5061 5052>,
			<6194 5609 5275 5089 5060 5053>,
			<6175 5599 5268 5089 5059 5054>,
			<6158 5589 5260 5089 5059 5055>,
			<6142 5580 5254 5089 5060 5056>,
			<6128 5573 5250 5089 5060 5057>,
			<6115 5566 5246 5090 5062 5058>,
			<6103 5560 5243 5091 5063 5059>,
			<6093 5555 5243 5092 5065 5060>,
			<6083 5551 5244 5094 5067 5062>,
			<6074 5549 5246 5097 5069 5064>,
			<6066 5557 5252 5101 5071 5066>,
			<6058 5572 5261 5106 5073 5067>,
			<6043 5572 5263 5110 5075 5069>,
			<6002 5542 5259 5112 5078 5071>,
			<5969 5516 5255 5115 5081 5073>,
			<5970 5517 5258 5122 5086 5077>,
			<5974 5522 5265 5131 5091 5081>,
			<5978 5523 5266 5133 5094 5085>,
			<5980 5516 5250 5127 5096 5088>,
			<5981 5509 5232 5119 5097 5090>,
			<5984 5506 5225 5108 5089 5083>,
			<5988 5504 5219 5094 5071 5067>,
			<5994 5504 5218 5090 5064 5060>,
			<6006 5506 5219 5091 5063 5059>,
			<6020 5509 5221 5091 5062 5059>,
			<6030 5517 5223 5092 5063 5060>,
			<6039 5535 5226 5094 5065 5062>,
			<6047 5552 5231 5097 5068 5064>,
			<6057 5568 5239 5099 5071 5066>,
			<6067 5584 5249 5102 5074 5068>,
			<6074 5603 5260 5106 5077 5071>,
			<6081 5623 5273 5110 5080 5074>,
			<6085 5644 5287 5115 5081 5076>,
			<6085 5666 5301 5121 5081 5075>,
			<6086 5686 5316 5126 5082 5074>,
			<6088 5704 5331 5129 5082 5073>,
			<6094 5721 5349 5131 5081 5072>,
			<6103 5727 5367 5134 5081 5072>,
			<6115 5716 5391 5147 5087 5077>,
			<6133 5693 5411 5162 5098 5086>,
			<6169 5658 5405 5168 5108 5095>,
			<6255 5606 5366 5172 5118 5104>,
			<6351 5600 5319 5160 5113 5100>,
			<6463 5616 5281 5132 5095 5087>,
			<6641 5694 5283 5130 5092 5085>,
			<6659 5732 5286 5132 5091 5084>,
			<6865 5829 5308 5140 5095 5086>,
			<7480 5992 5333 5148 5099 5091>,
			<8741 6272 5383 5157 5103 5093>,
			<11071 6782 5435 5153 5098 5087>,
			<15007 7970 5567 5165 5098 5092>,
			<21642 10001 5956 5195 5109 5098>,
			<32959 13584 6836 5254 5129 5111>,
			<32959 13584 6836 5254 5129 5111>,
			<32959 13584 6836 5254 5129 5111>;
	};
};
